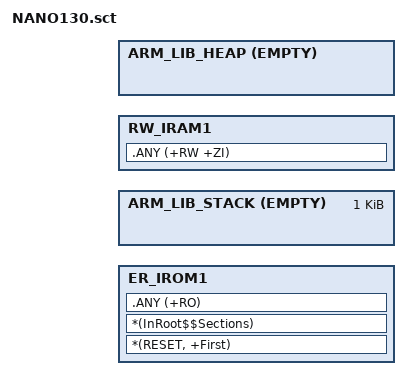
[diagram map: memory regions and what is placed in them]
#! armcc -E

/* Device specific values */
/* Tools provide -DMBED_ROM_START=0x0 -DMBED_ROM_SIZE=0x20000 -DMBED_RAM_START=0x20000000 -DMBED_RAM_SIZE=0x4000  */
/* Vectors in RAM */
#define VECTORS     (0)   /* This value must match NVIC_NUM_VECTORS */
#define SPIM_CCM_START  (MBED_RAM_START + 0x20000)
#define SPIM_CCM_END    (MBED_RAM_START + MBED_RAM_SIZE)

/* Common - Do not change */

#if !defined(MBED_APP_START)
  #define MBED_APP_START  MBED_ROM_START
#endif

#if !defined(MBED_APP_SIZE)
  #define MBED_APP_SIZE  MBED_ROM_SIZE
#endif

#if !defined(MBED_BOOT_STACK_SIZE)
  #define MBED_BOOT_STACK_SIZE      0x400
#endif

/* Round up VECTORS_SIZE to 8 bytes */
#define VECTORS_SIZE (((VECTORS * 4) + 7) AND ~7)

LR_IROM1  MBED_APP_START  MBED_APP_SIZE  {
  ER_IROM1  MBED_APP_START  MBED_APP_SIZE  {  ; load address = execution address
   *(RESET, +First)
   *(InRoot$$Sections)
   .ANY (+RO)
  }

  ARM_LIB_STACK  MBED_RAM_START  EMPTY  MBED_BOOT_STACK_SIZE {
  }

  RW_IRAM1  AlignExpr(+0, 16)  {  ; 16 byte-aligned
   .ANY (+RW +ZI)
  }
  
  ARM_LIB_HEAP  AlignExpr(+0, 16)  EMPTY  (MBED_RAM_START + MBED_RAM_SIZE - AlignExpr(ImageLimit(RW_IRAM1), 16))  {
  }
}
ScatterAssert(LoadLimit(LR_IROM1) <= (MBED_APP_START + MBED_APP_SIZE))  ; 128 KB APROM
ScatterAssert(ImageLimit(ARM_LIB_HEAP) <= (MBED_RAM_START + MBED_RAM_SIZE))   ; 16 KB SRAM
